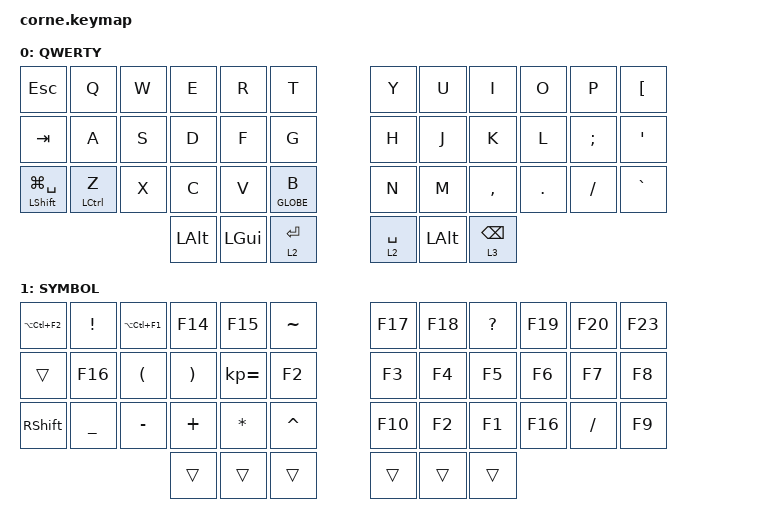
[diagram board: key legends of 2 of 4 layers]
/*
 * Copyright (c) 2020 The ZMK Contributors
 *
 * SPDX-License-Identifier: MIT
 * To use home rows - &hm LSHFT F
 *
 * For edit
 * https://nickcoutsos.github.io/keymap-editor/
 */

#include <behaviors.dtsi>
#include <dt-bindings/zmk/bt.h>
#include <dt-bindings/zmk/keys.h>

#define QWERTY 0
#define SYMBOL 1
#define NAVI 2
#define ADJUST 3

/ {
    behaviors {
        hm: homerow_mods {
            compatible = "zmk,behavior-hold-tap";
            label = "HOMEROW_MODS";
            #binding-cells = <2>;
            tapping-term-ms = <200>;
            quick_tap_ms = <0>;
            flavor = "tap-preferred";
            bindings = <&kp>, <&kp>;
        };
    };

    combos {
        compatible = "zmk,combos";

        ParaLeft {
            bindings = <&kp LA(S)>;
            key-positions = <4 5>;
            timeout-ms = <20>;
        };

        ParaRight {
            bindings = <&kp LA(D)>;
            key-positions = <6 7>;
            timeout-ms = <20>;
        };

        BrakLeft {
            bindings = <&kp LA(LEFT_BRACKET)>;
            key-positions = <16 17>;
            timeout-ms = <20>;
        };

        BrakRight {
            bindings = <&kp LA(J)>;
            key-positions = <18 19>;
            timeout-ms = <20>;
        };

        BraceLeft {
            bindings = <&kp LA(LEFT_BRACE)>;
            key-positions = <28 29>;
            timeout-ms = <20>;
        };

        BraceRight {
            bindings = <&kp LA(RIGHT_BRACE)>;
            key-positions = <30 31>;
            timeout-ms = <20>;
        };

        DoubleQuote {
            bindings = <&kp LA(SQT)>;
            key-positions = <15 16>;
            timeout-ms = <20>;
        };

        SingleQuote {
            bindings = <&kp LA(SEMICOLON)>;
            key-positions = <19 20>;
            timeout-ms = <20>;
        };

        //LangRu {
        //    bindings = <&kp LG(F11)>;
        //    key-positions = <0 1>;
        //    timeout-ms = <20>;
        //};
        //LangUs {
        //   bindings = <&kp LG(F12)>;
        //    key-positions = <10 11>;
        //    timeout-ms = <20>;
        //};
        //LangRuL {
        //    bindings = <&kp LG(F11)>;
        //    key-positions = <36 38>;
        //    timeout-ms = <20>;
        //};
        //LangUsL {
        //    bindings = <&kp LG(F12)>;
        //    key-positions = <39 41>;
        //    timeout-ms = <20>;
        //};

        TildaSign {
            bindings = <&kp LA(TILDE)>;
            key-positions = <0 12>;
            timeout-ms = <20>;
        };

        GraveSign {
            bindings = <&kp LA(GRAVE)>;
            key-positions = <12 24>;
            timeout-ms = <20>;
        };

        MinusSign {
            bindings = <&kp LA(X)>;
            key-positions = <3 4>;
            timeout-ms = <20>;
        };

        PlusSign {
            bindings = <&kp LA(C)>;
            key-positions = <2 3>;
            timeout-ms = <20>;
        };

        UnderscoreSign {
            bindings = <&kp LA(UNDERSCORE)>;
            key-positions = <7 8>;
            timeout-ms = <20>;
        };

        PipeSign {
            bindings = <&kp LA(PIPE)>;
            key-positions = <8 9>;
            timeout-ms = <20>;
        };

        modify {
            bindings = <&kp LG(LEFT_ALT)>;
            key-positions = <40 41>;
            layers = <0>;
            timeout-ms = <20>;
        };

        mode-left {
            bindings = <&kp LC(LEFT_ALT)>;
            key-positions = <39 40>;
            timeout-ms = <20>;
            layers = <0>;
        };

        modify-full-left {
            bindings = <&kp LC(LG(LEFT_ALT))>;
            key-positions = <39 40 41>;
            timeout-ms = <20>;
            layers = <0>;
        };

        modify-full-right {
            bindings = <&kp LC(LG(LEFT_ALT))>;
            key-positions = <36 37 38>;
            timeout-ms = <20>;
            layers = <0>;
        };

        modifay-left-right {
            bindings = <&kp LC(LEFT_ALT)>;
            key-positions = <37 38>;
            timeout-ms = <20>;
            layers = <0>;
        };
    };

    keymap {
        compatible = "zmk,keymap";

        default_layer {
            // .---------------------------------------------------------.       .-----------------------------------------------------------.
            // |    ⎋    |    Q    |    W   |   E    |    R    |    T    |       |   Y   |    U    |    I    |    O    |     P    |    [     |
            // |---------+---------+--------+--------+---------+---------|       |-------+---------+---------+---------+----------+----------|
            // |    ⇥    |    A    |    S   |    D   |    F    |    G    |       |   H   |    J    |    K    |    L    |    ;     |     '    |
            // |---------+---------+--------+--------+---------+---------|       |-------+---------+---------+---------+----------+----------|
            // |   ⇧/🌐  |  ^/Z    |    X   |   C    |    V    |    B    |       |   N   |    M    |    ,    |    .    |     /    |  `/⌥     |
            // '---------------------------------+--------+----+---------+       |-------+---------+---------+-------------------------------'
            //                                   |   ⌥    |   ⌘  |  L3/⏎ |       |  L2/␣ |  L1  |  L3/⌫  |
            //                                   '--------+------+-------'       '-------+------+--------'

            label = "QWERTY";
            bindings = <
&kp ESC                   &kp Q               &kp W  &kp E     &kp R     &kp T          &kp Y        &kp U         &kp I            &kp O    &kp P     &kp LBKT
&kp TAB                   &kp A               &kp S  &kp D     &kp F     &kp G          &kp H        &kp J         &kp K            &kp L    &kp SEMI  &kp SQT
&mt LEFT_SHIFT LG(SPACE)  &mt LEFT_CONTROL Z  &kp X  &kp C     &kp V     &hm GLOBE B    &kp N        &kp M         &kp COMMA        &kp DOT  &kp FSLH  &kp GRAVE
                                                     &kp LALT  &kp LGUI  &lt 2 RET      &lt 2 SPACE  &kp LEFT_ALT  &lt 3 BACKSPACE
            >;
        };

        symbol_layer {
            // .--------------------------------------------------------------.       .-----------------------------------------------------------.
            // |        %     |    !    |    @   |   #    |    $    |    ~    |       |   &   |    |    |    ?    |    :    |     ;    |    `     |
            // |--------------+---------+--------+--------+---------+---------|       |-------+---------+---------+---------+----------+----------|
            // |              |    .    |    (   |   )    |    =    |    >    |       |   [   |    ]    |    {    |    }    |     '    |     "    |
            // |--------------+---------+--------+--------+---------+---------|       |-------+---------+---------+---------+----------+----------|
            // |              |    _    |    -   |   +    |    *    |    ^    |       |   <   |    >    |    ,    |    .    |     /    |     \    |
            // '---------------------------------+--------+---------+---------+       |-------+---------+---------+-------------------------------'
            //                                   |        |         |         |       |       |         |         |
            //                                   '--------+---------+---------'       '-------+---------+---------'

            label = "SYMBOL";
            bindings = <
&kp LA(LC(F2))  &kp EXCL   &kp LA(LC(F1))  &kp F14   &kp F15       &kp TILDE    &kp F17  &kp F18  &kp QUESTION  &kp F19  &kp F20    &kp F23
&trans          &kp F16    &kp LPAR        &kp RPAR  &kp KP_EQUAL  &kp F2       &kp F3   &kp F4   &kp F5        &kp F6   &kp F7     &kp F8
&kp RSHIFT      &kp UNDER  &kp MINUS       &kp PLUS  &kp STAR      &kp CARET    &kp F10  &kp F2   &kp F1        &kp F16  &kp SLASH  &kp F9
                                           &trans    &trans        &trans       &trans   &trans   &trans
            >;
        };

        adjust_layer {
            // .----------------------------------------------------------------.       .-----------------------------------------------------------------.
            // |       .        |   7    |   8   |   9    |    ^⌘T   |    ^⌘T   |       |    ↑    |    ⌘◀    |    ▲    |    ⌘▶   |   HOME   |      ⌫      |
            // |----------------+-------+-------+---------+----------+----------|       |---------+----------+---------+---------+----------+-------------|
            // |       0        |    4  |    5   |   6    |    ⌥D    |   ^⌘T    |       |    ↓    |     ◀    |    ▼    |     ▶   |   END    |             |
            // |----------------+-------+-------+---------+----------+----------|       |---------+----------+---------+---------+----------+-------------|
            // |       ⇧        |   1    |   2   |   3    |    ⌥W    |    ^␣    |       |   ⇧⌥◀   |    ⇧⌥▶   |    ^;   |         |    ^◀    |      ^▶     |
            // '---------------------------------+--------+----------+----------+       |---------+----------+---------+----------------------------------'
            //                                   |        |     ^    |          |       |         |          |         |
            //                                   '--------+----------+----------'       '---------+----------+---------'

            label = "ADJUST";
            bindings = <
&kp DOT         &kp N7  &kp N8  &kp N9  &kp LC(LG(T))     &kp LC(T)        &kp PAGE_UP       &kp LG(LEFT_ARROW)  &kp UP_ARROW    &kp LG(RIGHT)    &kp HOME      &kp BACKSPACE
&kp N0          &kp N4  &kp N5  &kp N6  &trans            &kp LA(ENTER)    &kp PAGE_DOWN     &kp LEFT_ARROW      &kp DOWN_ARROW  &kp RIGHT_ARROW  &kp END       &trans
&kp LEFT_SHIFT  &kp N1  &kp N2  &kp N3  &trans            &kp LC(SPACE)    &kp LS(LA(LEFT))  &kp LA(LS(RIGHT))   &kp LC(SEMI)    &trans           &kp LC(LEFT)  &kp LC(RIGHT)
                                &trans  &kp LEFT_CONTROL  &trans           &trans            &trans
            >;
        };

        config_layer {
            // .--------------------------------------------------------.       .--------------------------------------------------------------.
            // |CMD+CTRL+N1 |CMD+CTRL+N2|CMD+CTRL+N3|CMD+CTRL+N4|CMD+CTRL+R |CMD+CTRL+N5|  VOL+  | Trans | Trans | Trans | BT_SEL 0 | BT_SEL 1 |
            // |------------+-----------+-----------+-----------+-----------+-----------+--------+-------+-------+-------+----------+----------|
            // |   Trans    |   Trans   | CMD+CTRL+W|   Trans   |   Trans   |   Trans   |  VOL-  | Trans | Trans | Trans | BT_SEL 2 | BT_SEL 3 |
            // |------------+-----------+-----------+-----------+-----------+-----------+--------+-------+-------+-------+----------+----------|
            // |   Trans    |   Trans   |   Trans   |   Trans   |   Trans   |   Trans   |  MUTE  | Trans | Trans | Trans | BT_SEL 4 | BT_CLR   |
            // '------------------------+-----------+-----------+-----------+-----------+--------+-------+-------+---------------------------------'
            //                          |   Trans   |   Trans   |   Trans   |       Trans| Trans | Trans |
            //                          '-----------+-----------+-----------'       '-------+-------+-----'

            label = "CONFIG";
            bindings = <
&bt BT_PRV  &bt BT_NXT        &trans  &trans      &kp C_BRIGHTNESS_INC  &kp C_VOLUME_UP    &kp LA(LC(LG(Y)))  &kp LA(LC(LG(U)))  &kp LA(LC(LG(I)))  &kp LA(LC(LG(O)))  &kp LA(LC(LG(P)))  &trans
&bt BT_CLR  &trans            &trans  &trans      &kp C_BRIGHTNESS_DEC  &kp C_VOL_DN       &kp LA(LC(LG(H)))  &kp LA(LC(LG(J)))  &kp LA(LC(LG(K)))  &kp LA(LC(LG(L)))  &trans             &trans
&kp GLOBE   &kp LEFT_CONTROL  &trans  &kp C_PREV  &kp C_PLAY_PAUSE      &kp C_NEXT         &kp LA(LC(LG(N)))  &kp LA(LC(LG(M)))  &trans             &trans             &trans             &trans
                                      &trans      &trans                &trans             &trans             &trans             &trans
            >;
        };
    };
};
